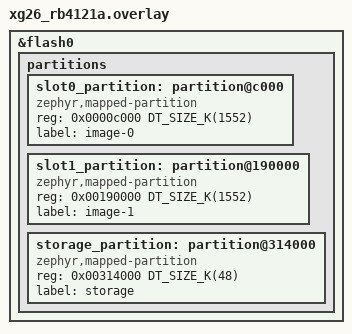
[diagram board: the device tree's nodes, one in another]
/*
 *	Copyright (c) 2026 Project CHIP Authors
 *	All rights reserved.
 *
 *	Licensed under the Apache License, Version 2.0 (the "License");
 *	you may not use this file except in compliance with the License.
 *	You may obtain a copy of the License at
 *
 *		http://www.apache.org/licenses/LICENSE-2.0
 *
 *	Unless required by applicable law or agreed to in writing, software
 *	distributed under the License is distributed on an "AS IS" BASIS
 *	WITHOUT WARRANTIES OR CONDITIONS OF ANY KIND, either express or implied.
 *	See the License for the specific language governing permissions and
 *	limitations under the License.
 */

/*
 * Internal flash (3200 KiB): boot (48) + slot0 (1552) + slot1 (1552) + storage (48).
 */
 
/delete-node/ &slot0_partition;
/delete-node/ &slot1_partition;
/delete-node/ &storage_partition;

&flash0 {
	partitions {
		slot0_partition: partition@c000 {
			compatible = "zephyr,mapped-partition";
			reg = <0x0000c000 DT_SIZE_K(1552)>;
			label = "image-0";
		};

		slot1_partition: partition@190000 {
			compatible = "zephyr,mapped-partition";
			reg = <0x00190000 DT_SIZE_K(1552)>;
			label = "image-1";
		};

		storage_partition: partition@314000 {
			compatible = "zephyr,mapped-partition";
			reg = <0x00314000 DT_SIZE_K(48)>;
			label = "storage";
		};
	};
};
